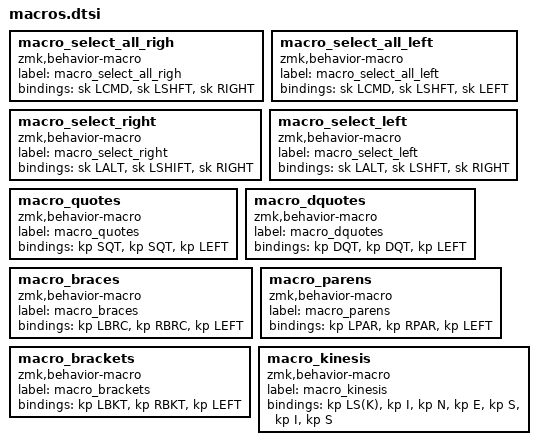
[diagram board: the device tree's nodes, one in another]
macro_select_all_righ: macro_select_all_righ{
compatible = "zmk,behavior-macro";
label = "macro_select_all_righ";
#binding-cells = <0>;
bindings = <&sk LCMD>, <&sk LSHFT>, <&sk RIGHT>;
};
macro_select_all_left: macro_select_all_left{
compatible = "zmk,behavior-macro";
label = "macro_select_all_left";
#binding-cells = <0>;
bindings = <&sk LCMD>, <&sk LSHFT>, <&sk LEFT>;
};
macro_select_right: macro_select_right{
compatible = "zmk,behavior-macro";
label = "macro_select_right";
#binding-cells = <0>;
bindings = <&sk LALT>, <&sk LSHIFT>, <&sk RIGHT>;
};
macro_select_left: macro_select_left{
compatible = "zmk,behavior-macro";
label = "macro_select_left";
#binding-cells = <0>;
bindings = <&sk LALT>, <&sk LSHFT>, <&sk RIGHT>;
};
macro_quotes: macro_quotes{
compatible = "zmk,behavior-macro";
label = "macro_quotes";
#binding-cells = <0>;
bindings = <&kp SQT>, <&kp SQT>, <&kp LEFT>;
};
macro_dquotes: macro_dquotes{
compatible = "zmk,behavior-macro";
label = "macro_dquotes";
#binding-cells = <0>;
bindings = <&kp DQT>, <&kp DQT>, <&kp LEFT>;
};
macro_braces: macro_braces{
compatible = "zmk,behavior-macro";
label = "macro_braces";
#binding-cells = <0>;
bindings = <&kp LBRC>, <&kp RBRC>, <&kp LEFT>;
};
macro_parens: macro_parens{
compatible = "zmk,behavior-macro";
label = "macro_parens";
#binding-cells = <0>;
bindings = <&kp LPAR>, <&kp RPAR>, <&kp LEFT>;
};
macro_brackets: macro_brackets{
compatible = "zmk,behavior-macro";
label = "macro_brackets";
#binding-cells = <0>;
bindings = <&kp LBKT>, <&kp RBKT>, <&kp LEFT>;
};
macro_kinesis: macro_kinesis{
compatible = "zmk,behavior-macro";
label = "macro_kinesis";
#binding-cells = <0>;
bindings = <&kp LS(K)>, <&kp I>, <&kp N>, <&kp E>, <&kp S>, <&kp I>, <&kp S>;
};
